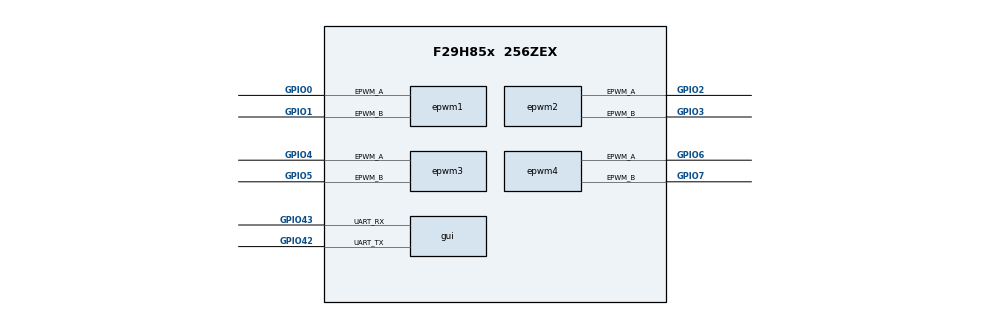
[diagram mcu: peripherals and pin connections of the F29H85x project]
/**
 * @cliArgs --device "F29H85x" --package "256ZEX" --part "F29H85x_256ZEX" --context "CPU1" --product "MCU_SDK_F29H85x@1.02.02.00"
 * @versions {"tool":"1.25.0+4237"}
 */

    
const divider15       = system.clockTree["PLL_REFDIV"];
divider15.divideValue = 1;

const multiplier1         = system.clockTree["PLL_IMULT"];
multiplier1.multiplyValue = 40;

const mux7       = system.clockTree["OSCCLKSRCSEL"];
mux7.inputSelect = "INTOSC2";

/**
 * Import the modules used in this configuration.
 */
const dlt       = scripting.addModule("/driverlib/dlt.js");
const epwm      = scripting.addModule("/driverlib/epwm.js", {}, false);
const epwm1     = epwm.addInstance();
const epwm2     = epwm.addInstance();
const epwm3     = epwm.addInstance();
const epwm4     = epwm.addInstance();
const gui       = scripting.addModule("/transfer/gui.js");

dlt.enableTagFilter          = true;
dlt.startTagReference        = 0x1;
dlt.startTagMask             = 0xFFFF;
dlt.endTagReference          = 0x20;
dlt.endTagMask               = 0xFFFF;
dlt.enableInterrupt          = ["DLT_INT_FIFO_TRIG"];
dlt.registerInterrupts       = true;
dlt.setFIFOTriggerLevel = 250;
dlt.periphClock.$name        = "driverlib_perClock5";
dlt.periphConfig.$name       = "driverlib_perConfig4";

epwm1.$name                                                    = "myEPWM1";
epwm1.epwmTimebase_period                                      = 4000;
epwm1.epwmTimebase_hsClockDiv                                  = "EPWM_HSCLOCK_DIVIDER_14";
epwm1.epwmTimebase_clockDiv                                    = "EPWM_CLOCK_DIVIDER_128";
epwm1.epwmCounterCompare_cmpA                                  = 1000;
epwm1.epwmCounterCompare_cmpB                                  = 500;
epwm1.epwmEventTrigger_enableInterrupt                         = true;
epwm1.epwmEventTrigger_interruptEventCount                     = "1";
epwm1.epwmTimebase_syncOutPulseMode                            = ["EPWM_SYNC_OUT_PULSE_ON_CNTR_ZERO"];
epwm1.epwmActionQualifier_EPWM_AQ_OUTPUT_A_ON_TIMEBASE_ZERO    = "EPWM_AQ_OUTPUT_HIGH";
epwm1.epwmActionQualifier_EPWM_AQ_OUTPUT_A_ON_TIMEBASE_UP_CMPA = "EPWM_AQ_OUTPUT_LOW";
epwm1.epwmActionQualifier_EPWM_AQ_OUTPUT_B_ON_TIMEBASE_ZERO    = "EPWM_AQ_OUTPUT_HIGH";
epwm1.epwmActionQualifier_EPWM_AQ_OUTPUT_B_ON_TIMEBASE_UP_CMPB = "EPWM_AQ_OUTPUT_LOW";
epwm1.epwmEventTrigger_registerInterrupts                      = true;
epwm1.epwmEventTrigger_interruptSource                         = "EPWM_INT_TBCTR_ZERO";
epwm1.epwm.$assign                                             = "EPWM1";
epwm1.epwm.epwm_aPin.$assign                                   = "GPIO0";
epwm1.epwm.epwm_bPin.$assign                                   = "GPIO1";
epwm1.periphClock.$name                                        = "driverlib_perClock0";
epwm1.periphConfig.$name                                       = "driverlib_perConfig0";
epwm1.epwmInt.interruptHandler                                 = "epwm1ISR";

epwm2.$name                                                    = "myEPWM2";
epwm2.epwmTimebase_period                                      = 4000;
epwm2.epwmTimebase_clockDiv                                    = "EPWM_CLOCK_DIVIDER_128";
epwm2.epwmTimebase_hsClockDiv                                  = "EPWM_HSCLOCK_DIVIDER_14";
epwm2.epwmTimebase_phaseEnable                                 = true;
epwm2.epwmTimebase_phaseShift                                  = 300;
epwm2.epwmCounterCompare_cmpA                                  = 1000;
epwm2.epwmCounterCompare_cmpB                                  = 500;
epwm2.epwmEventTrigger_enableInterrupt                         = true;
epwm2.epwmEventTrigger_interruptEventCount                     = "1";
epwm2.epwmTimebase_periodLoadEvent                             = "EPWM_SHADOW_LOAD_MODE_SYNC";
epwm2.epwmActionQualifier_EPWM_AQ_OUTPUT_A_ON_TIMEBASE_ZERO    = "EPWM_AQ_OUTPUT_HIGH";
epwm2.epwmActionQualifier_EPWM_AQ_OUTPUT_A_ON_TIMEBASE_UP_CMPA = "EPWM_AQ_OUTPUT_LOW";
epwm2.epwmActionQualifier_EPWM_AQ_OUTPUT_B_ON_TIMEBASE_ZERO    = "EPWM_AQ_OUTPUT_HIGH";
epwm2.epwmActionQualifier_EPWM_AQ_OUTPUT_B_ON_TIMEBASE_UP_CMPB = "EPWM_AQ_OUTPUT_LOW";
epwm2.epwmEventTrigger_registerInterrupts                      = true;
epwm2.epwmEventTrigger_interruptSource                         = "EPWM_INT_TBCTR_ZERO";
epwm2.epwm.$assign                                             = "EPWM2";
epwm2.epwm.epwm_aPin.$assign                                   = "GPIO2";
epwm2.epwm.epwm_bPin.$assign                                   = "GPIO3";
epwm2.periphClock.$name                                        = "driverlib_perClock1";
epwm2.periphConfig.$name                                       = "driverlib_perConfig1";
epwm2.epwmInt.interruptHandler                                 = "epwm2ISR";

epwm3.$name                                                    = "myEPWM3";
epwm3.epwmTimebase_period                                      = 4000;
epwm3.epwmTimebase_hsClockDiv                                  = "EPWM_HSCLOCK_DIVIDER_14";
epwm3.epwmTimebase_clockDiv                                    = "EPWM_CLOCK_DIVIDER_128";
epwm3.epwmTimebase_phaseEnable                                 = true;
epwm3.epwmTimebase_phaseShift                                  = 600;
epwm3.epwmCounterCompare_cmpA                                  = 1000;
epwm3.epwmCounterCompare_cmpB                                  = 500;
epwm3.epwmEventTrigger_enableInterrupt                         = true;
epwm3.epwmEventTrigger_interruptEventCount                     = "1";
epwm3.epwmTimebase_periodLoadEvent                             = "EPWM_SHADOW_LOAD_MODE_SYNC";
epwm3.epwmActionQualifier_EPWM_AQ_OUTPUT_A_ON_TIMEBASE_ZERO    = "EPWM_AQ_OUTPUT_HIGH";
epwm3.epwmActionQualifier_EPWM_AQ_OUTPUT_A_ON_TIMEBASE_UP_CMPA = "EPWM_AQ_OUTPUT_LOW";
epwm3.epwmActionQualifier_EPWM_AQ_OUTPUT_B_ON_TIMEBASE_ZERO    = "EPWM_AQ_OUTPUT_HIGH";
epwm3.epwmActionQualifier_EPWM_AQ_OUTPUT_B_ON_TIMEBASE_UP_CMPB = "EPWM_AQ_OUTPUT_LOW";
epwm3.epwmEventTrigger_registerInterrupts                      = true;
epwm3.epwmEventTrigger_interruptSource                         = "EPWM_INT_TBCTR_ZERO";
epwm3.epwm.$assign                                             = "EPWM3";
epwm3.epwm.epwm_aPin.$assign                                   = "GPIO4";
epwm3.epwm.epwm_bPin.$assign                                   = "GPIO5";
epwm3.periphClock.$name                                        = "driverlib_perClock2";
epwm3.periphConfig.$name                                       = "driverlib_perConfig2";
epwm3.epwmInt.interruptHandler                                 = "epwm3ISR";

epwm4.$name                                                    = "myEPWM4";
epwm4.epwmTimebase_period                                      = 4000;
epwm4.epwmTimebase_clockDiv                                    = "EPWM_CLOCK_DIVIDER_128";
epwm4.epwmTimebase_hsClockDiv                                  = "EPWM_HSCLOCK_DIVIDER_14";
epwm4.epwmTimebase_phaseEnable                                 = true;
epwm4.epwmTimebase_phaseShift                                  = 900;
epwm4.epwmCounterCompare_cmpA                                  = 1000;
epwm4.epwmCounterCompare_cmpB                                  = 500;
epwm4.epwmEventTrigger_enableInterrupt                         = true;
epwm4.epwmEventTrigger_interruptEventCount                     = "1";
epwm4.epwmTimebase_periodLoadEvent                             = "EPWM_SHADOW_LOAD_MODE_SYNC";
epwm4.epwmActionQualifier_EPWM_AQ_OUTPUT_A_ON_TIMEBASE_ZERO    = "EPWM_AQ_OUTPUT_HIGH";
epwm4.epwmActionQualifier_EPWM_AQ_OUTPUT_A_ON_TIMEBASE_UP_CMPA = "EPWM_AQ_OUTPUT_LOW";
epwm4.epwmActionQualifier_EPWM_AQ_OUTPUT_B_ON_TIMEBASE_ZERO    = "EPWM_AQ_OUTPUT_HIGH";
epwm4.epwmActionQualifier_EPWM_AQ_OUTPUT_B_ON_TIMEBASE_UP_CMPB = "EPWM_AQ_OUTPUT_LOW";
epwm4.epwmEventTrigger_registerInterrupts                      = true;
epwm4.epwmEventTrigger_interruptSource                         = "EPWM_INT_TBCTR_ZERO";
epwm4.epwm.$assign                                             = "EPWM4";
epwm4.epwm.epwm_aPin.$assign                                   = "GPIO6";
epwm4.epwm.epwm_bPin.$assign                                   = "GPIO7";
epwm4.periphClock.$name                                        = "driverlib_perClock3";
epwm4.periphConfig.$name                                       = "driverlib_perConfig3";
epwm4.epwmInt.interruptHandler                                 = "epwm4ISR";

gui.dltlogger                                       = true;
gui.customlogger                                    = true;
gui.exporter.$name                                  = "myEXPORT0";
gui.exporter.packageMode                            = "START/END";
gui.exporter.txStartByte                            = 0xAA;
gui.exporter.txEndByte                              = 0xFF;
gui.exporter.comsLinkModule.uart.uart_txPin.$assign = "GPIO42";
gui.exporter.comsLinkModule.uart.uart_rxPin.$assign = "GPIO43";
gui.exporter.comsLinkModule.txQual.$name            = "myGPIOQUAL0";
gui.exporter.comsLinkModule.rxQual.$name            = "myGPIOQUAL1";
gui.exporter.comsLinkModule.periphClock.$name       = "driverlib_perClock4";
gui.exporter.comsLinkModule.periphConfig.$name      = "driverlib_perConfig5";
gui.exporter.txKeyValuePairs.create(2);
gui.exporter.txKeyValuePairs[1].$name               = "DLTlog";
gui.exporter.txKeyValuePairs[1].valType             = "uint32_t";
gui.exporter.txKeyValuePairs[1].keyValueID          = 49;
gui.DLTModule.$name                                 = "myDLTLOG0";
gui.guiProjectName                                      = "transfer_epwm_dlt";


/**
 * Pinmux solution for unlocked pins/peripherals. This ensures that minor changes to the automatic solver in a future
 * version of the tool will not impact the pinmux you originally saw.  These lines can be completely deleted in order to
 * re-solve from scratch.
 */
gui.exporter.comsLinkModule.uart.$suggestSolution = "UARTA";
